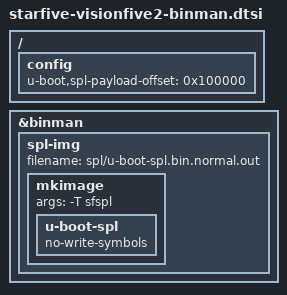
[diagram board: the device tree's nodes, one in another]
// SPDX-License-Identifier: GPL-2.0 OR MIT
/*
 * Copyright (C) 2023 StarFive Technology Co., Ltd.
 */

#include "binman.dtsi"

/ {
	config {
		bootph-pre-ram;
		u-boot,spl-payload-offset = <0x100000>;
	};
};

&binman {
	spl-img {
		filename = "spl/u-boot-spl.bin.normal.out";

		mkimage {
			args = "-T sfspl";

			u-boot-spl {
				no-write-symbols;
			};
		};
	};
};
